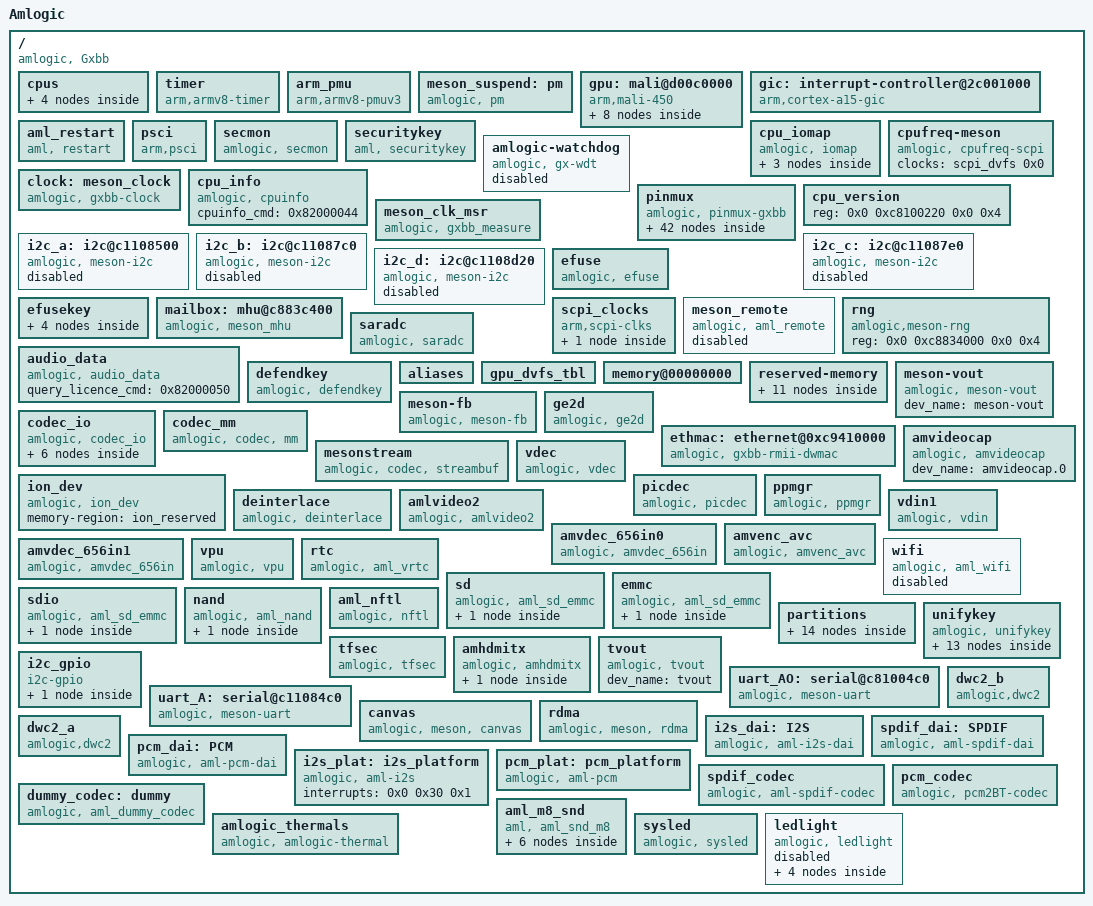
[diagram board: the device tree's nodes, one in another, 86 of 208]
/dts-v1/;

#include <dt-bindings/clock/gxbb.h>
#include <dt-bindings/gpio/gxbb.h>
#include <dt-bindings/gpio/gpio.h>
#include <dt-bindings/reset/aml_gxbb.h>
#include <dt-bindings/thermal/thermal.h>
#include <dt-bindings/interrupt-controller/arm-gic.h>
#include <dt-bindings/input/input.h>
#include <dt-bindings/input/meson_rc.h>

/ {
	model = "Amlogic";
	compatible = "amlogic, Gxbb";
	amlogic-dt-id = "gxbb_p201_q5";
	interrupt-parent = <&gic>;
	#address-cells = <0x2>;
	#size-cells = <0x2>;

	cpus: cpus {
		#address-cells = <0x2>;
		#size-cells = <0x0>;
		#cooling-cells = <2>;		/* min followed by max */

		cpu0: cpu@0 {
			device_type = "cpu";
			compatible = "arm,cortex-a53", "arm,armv8";
			reg = <0x0 0x0>;
			enable-method = "psci";
		};

		cpu1: cpu@1 {
			device_type = "cpu";
			compatible = "arm,cortex-a53", "arm,armv8";
			reg = <0x0 0x1>;
			enable-method = "psci";
		};

		cpu2: cpu@2 {
			device_type = "cpu";
			compatible = "arm,cortex-a53", "arm,armv8";
			reg = <0x0 0x2>;
			enable-method = "psci";
		};

		cpu3: cpu@3 {
			device_type = "cpu";
			compatible = "arm,cortex-a53", "arm,armv8";
			reg = <0x0 0x3>;
			enable-method = "psci";
		};
	};

	timer {
		compatible = "arm,armv8-timer";
		interrupts = <GIC_PPI 13 0xff01>,
				<GIC_PPI 14 0xff01>,
				<GIC_PPI 11 0xff01>,
				<GIC_PPI 10 0xff01>;
	};

	arm_pmu {
		compatible = "arm,armv8-pmuv3";
		interrupts = <0x0 0x89 0x4>,
					<0x0 0x8a 0x4>,
					<0x0 0x99 0x4>,
					<0x0 0x9a 0x4>;
	};

	meson_suspend: pm {
		compatible = "amlogic, pm";
		device_name = "aml_pm";
		gxbaby-suspend;
		reg = <0x0 0xc81000a8 0x0 0x4>,
			<0x0 0xc810023c 0x0 0x4>;
	};

	gpu: mali@d00c0000 {
		#cooling-cells = <2>;					/* min followed by max */
		compatible = "arm,mali-450";
		interrupt-parent = <&gic>;
		reg = <0x0 0xd00c0000 0x0 0x40000>,		/*mali APB bus base address*/
			<0x0 0xc883c000 0x0 0x4 >,			/*hiubus base address for gpu clk cntl*/
			<0x0 0xc8100000 0x0 0x4>;			/*aobus  base address for gpu pmu domain*/
												/*hiubus base address for gpu clk cntl*/
		interrupts = <0x0 0xa0 0x4 0x0 0xa1 0x4 0x0 0xa2 0x4 0x0 0xa3 0x4 0x0 0xa4 0x4 0x0 0xa5 0x4 0x0 0xa6 0x4 0x0 0xa7 0x4 0x0 0xa8 0x4 0x0 0xa9 0x4>;
		interrupt-names = "IRQGP", "IRQGPMMU", "IRQPP", "IRQPMU", "IRQPP0", "IRQPPMMU0", "IRQPP1", "IRQPPMMU1", "IRQPP2", "IRQPPMMU2";
		pmu_domain_config = <0x1 0x2 0x4 0x4 0x0 0x0 0x0 0x0 0x0 0x1 0x2 0x0>;
		pmu_switch_delay = <0xffff>;
		num_of_pp = <0x3>;
		def_clock = <0x3>;
		sc_mpp = <0x3>;							/* number of pp used most of time.*/
		tbl = <&clk125_cfg &clk285_cfg &clk400_cfg &clk500_cfg &clk666_cfg &clk800_cfg>;
		clocks = <&clock CLK_FPLL_DIV3>,
				<&clock CLK_FPLL_DIV4>,
				<&clock CLK_FPLL_DIV5>,
				<&clock CLK_FPLL_DIV7>,
				<&clock GP0_PLL>,
				<&clock CLK_MALI>,
				<&clock CLK_MALI_0>,
				<&clock CLK_MALI_1>;
		clock-names = "fclk_div3", "fclk_div4", "fclk_div5", "fclk_div7", "gp0_pll", "clk_mali", "clk_mali_0", "clk_mali_1";
		/*control_interval x keep_count == 900 - 1000ms */
		control_interval = <0xc8>;
		dvfs_tbl = <&gpu_dvfs_tbl>;

		clk125_cfg: clk125_cfg {
			clk_freq = <0x7735940>;
			clk_parent = "fclk_div4";
			clkp_freq = <0x1dcd6500>;
			voltage = <0x47e>;
			keep_count = <0x5>;
			threshold = <0x1e 0x78>;
		};

		clk250_cfg: clk250_cfg {
			clk_freq = <0xee6b280>;
			clk_parent = "fclk_div4";
			clkp_freq = <0x1dcd6500>;
			voltage = <0x47e>;
			keep_count = <0x5>;
			threshold = <0x50 0xaa>;
			/*125 = 250*(125/250), 50= 60-10*/
		};

		clk285_cfg: clk285_cfg {
			clk_freq = <0x10fcc140>;
			clk_parent = "fclk_div7";
			clkp_freq = <0x10fcc140>;
			voltage = <0x47e>;
			keep_count = <0x5>;
			threshold = <0x64 0xbe>;
			/*109 = 250*(125/285)*/
		};

		clk400_cfg: clk400_cfg {
			clk_freq = <0x17d78400>;
			clk_parent = "fclk_div5";
			clkp_freq = <0x17d78400>;
			voltage = <0x47e>;
			keep_count = <0x5>;
			threshold = <0x98 0xcf>;
			/*178 = 250*(285/400)*/
		};

		clk500_cfg: clk500_cfg {
			clk_freq = <0x1dcd6500>;
			clk_parent = "fclk_div4";
			clkp_freq = <0x1dcd6500>;
			voltage = <0x47e>;
			keep_count = <0x5>;
			threshold = <0xb4 0xdc>;
			/*200=250*(400/500)*/
		};

		clk666_cfg: clk666_cfg {
			clk_freq = <0x27b25a80>;
			clk_parent = "fclk_div3";
			clkp_freq = <0x27b25a80>;
			voltage = <0x47e>;
			keep_count = <0x5>;
			threshold = <0xd2 0xec>;
			/*187.5=250*(500/666.6)*/
		};

		clk750_cfg:clk750_cfg {
			clk_freq = <0x2c588a00>;
			clk_parent = "gp0_pll";
			clkp_freq = <0x2c588a00>;
			voltage = <0x47e>;
			keep_count = <0x1>;
			threshold = <0xd5 0xff>;
			/*223=250*(666.0/744.0), 223+7=230*/
		};

		clk800_cfg: clk800_cfg {
			clk_freq = <0x2f34f600>;
			clk_parent = "gp0_pll";
			clkp_freq = <0x2f34f600>;
			voltage = <0x47e>;
			keep_count = <0x5>;
			threshold = <0xe6 0xff>;
		};
	};

	gic: interrupt-controller@2c001000 {
		compatible = "arm,cortex-a15-gic", "arm,cortex-a9-gic";
		#interrupt-cells = <0x3>;
		#address-cells = <0x0>;
		interrupt-controller;
		reg = <0x0 0xc4301000 0x0 0x1000>,
			<0x0 0xc4302000 0x0 0x100>;
		interrupts = <GIC_PPI 0x9 0xf04>;
	};

	aml_restart {
		compatible = "aml, restart";
		sys_reset = <0x84000009>;
		sys_poweroff = <0x84000008>;
	};

	psci {
		compatible = "arm,psci";
		method = "smc";
		cpu_suspend = <0xc4000001>;
		cpu_off = <0x84000002>;
		cpu_on = <0xc4000003>;
		migrate = <0xc4000005>;
	};

	secmon {
		compatible = "amlogic, secmon";
		memory-region = <&secmon_reserved>;
		in_base_func = <0x82000020>;
		out_base_func = <0x82000021>;
	};
/*
	securitykey {
		compatible = "aml, securitykey";
		storage_query = <0x82000060>;
		storage_read = <0x82000061>;
		storage_write = <0x82000062>;
		storage_tell = <0x82000063>;
		storage_verify = <0x82000064>;
		storage_status = <0x82000065>;
		storage_list = <0x82000067>;
		storage_remove = <0x82000068>;
		storage_in_func = <0x82000023>;
		storage_out_func = <0x82000024>;
		storage_block_func = <0x82000025>;
		storage_size_func = <0x82000027>;
	};
*/
	securitykey {
		compatible = "aml, securitykey";
		storage_query = <0x82000060>;
		storage_read = <0x82000061>;
		storage_write = <0x82000062>;
		storage_tell = <0x82000063>;
		storage_verify = <0x82000064>;
		storage_status = <0x82000065>;
		storage_list = <0x82000067>;
		storage_remove = <0x82000068>;
		storage_in_func = <0x82000023>;
		storage_out_func = <0x82000024>;
		storage_block_func = <0x82000025>;
		storage_size_func = <0x82000027>;
		storage_set_enctype = <0x8200006A>;
		storage_get_enctype = <0x8200006B>;
		storage_version = <0x8200006C>;
	};

	cpu_iomap {
		compatible = "amlogic, iomap";
		#address-cells = <0x2>;
		#size-cells = <0x2>;
		ranges;

		io_cbus_base {
			reg = <0x0 0xc1100000 0x0 0x100000>;
		};

		io_apb_base {
			reg = <0x0 0xd0000000 0x0 0x200000>;
		};

		io_aobus_base {
			reg = <0x0 0xc8100000 0x0 0x100000>;
		};
	};

	cpufreq-meson {
		compatible = "amlogic, cpufreq-scpi";
		status = "okay";
		clocks = <&scpi_dvfs 0x0>;
		clock-names = "cpu_clk";
	};

	amlogic-watchdog {
		compatible = "amlogic, gx-wdt";
		status = "disable";
		default_timeout = <0xa>;
		reset_watchdog_method = <0x1>;		//0:sysfs, 1:kernel
		reset_watchdog_time = <0x2>;
		shutdown_timeout = <0xa>;
		firmware_timeout = <0x6>;
		suspend_timeout = <0x6>;
		reg = <0x0 0xc11098d0 0x0 0x10>;
		clocks = <&clock CLK_XTAL>;
	};

	clock: meson_clock {
		compatible = "amlogic, gxbb-clock";
		reg = <0x0 0xc883c000 0x0 0x1000>,		/* HIU BUS*/
			<0x0 0xc8100000 0x0 0x1000>;		//AOBUS
		#clock-cells = <0x1>;
		#reset-cells = <0x1>;
		sys_max = <0x5b8d8000>;
	};

	cpu_info {
		compatible = "amlogic, cpuinfo";
		cpuinfo_cmd = <0x82000044>;
	};

	pinmux: pinmux {
		compatible = "amlogic, pinmux-gxbb";
		dev_name = "pinmux";
		#pinmux-cells = <0x2>;
		#address-cells = <0x2>;
		#size-cells = <0x2>;
		reg = <0x0 0xc1109880 0x0 0x10>;
		ranges;

		gpio: banks@c11080b0 {
			reg = <0x0 0xc88344b0 0x0 0x28>,
				<0x0 0xc88344e8 0x0 0x14>,
				<0x0 0xc8834520 0x0 0x14>,
				<0x0 0xc8834430 0x0 0x40>;
			reg-names = "mux", "pull", "pull-enable", "gpio";
			gpio-controller;
			#gpio-cells = <0x2>;
		};

		gpio_ao: ao-bank@c1108030 {
			reg = <0x0 0xc8100014 0x0 0x8>,
				<0x0 0xc810002c 0x0 0x4>,
				<0x0 0xc8100024 0x0 0x8>;
			reg-names = "mux", "pull", "gpio";
			gpio-controller;
			#gpio-cells = <0x2>;
		};

		eth_pins: eth_pins {
			amlogic,setmask = <0x6 0x3fff>;
			amlogic,clrmask = <6 0xc000>,
							<5 0x3c0000f0>,
							<4  0x300>;
			amlogic,pins = "GPIOZ_0", "GPIOZ_1", "GPIOZ_2",
				"GPIOZ_3", "GPIOZ_4", "GPIOZ_5", "GPIOZ_6",
				"GPIOZ_7", "GPIOZ_8", "GPIOZ_9", "GPIOZ_10",
				"GPIOZ_11", "GPIOZ_12", "GPIOZ_13", "GPIOZ_15";
		};

		remote_pins: remote_pin {
			amlogic,setmask = <AO 0x1>;
			amlogic,pins = "GPIOAO_7";
		};

		ao_uart_pins: ao_uart {
			amlogic,setmask = <AO 0x1800>;
			amlogic,pins = "GPIOAO_0", "GPIOAO_1";
		};

		ao_b_uart_pins: ao_b_uart {
			amlogic,setmask = <AO 0x1800000>;
			amlogic,pins = "GPIOAO_4", "GPIOAO_5";
		};

		a_uart_pins: a_uart {
			amlogic,setmask = <0x4 0x3c00>;
			amlogic,pins = "GPIOX_12", "GPIOX_13", "GPIOX_14", "GPIOX_15";
		};

		b_uart_pins: b_uart {
			amlogic,setmask = <0x2 0x30000000>;
			amlogic,pins = "GPIODV_24", "GPIODV_25";
		};

		c_uart_pins: c_uart {
			amlogic,setmask = <0x1 0xc0000>;
			amlogic,pins = "GPIOY_13", "GPIOY_14";
		};

		wifi_32k_pins: wifi_32k_pins {
			amlogic,setmask = <0x2 0x40000000>;
			amlogic,clrmask = <0x2 0x400000 0x3 0x8000>;
			amlogic,pins = "GPIOX_19";
		};

		sd_clk_cmd_pins: sd_clk_cmd_pins {
			amlogic,setmask = <0x2 0xc00 AO 0x1800>;
			amlogic,pins = "CARD_2", "CARD_3";		/* CARD_2:CLK, CARD_3:CMD */
			amlogic,enable-output = <0x1>;			/* 0:output, 1:input */
			amlogic,pullup = <0x1>;
			amlogic,pullupen = <0x1>;
		};

		sd_all_pins: sd_all_pins {
			amlogic,setmask = <0x2 0xfc00 0x10 0x1800>;
			amlogic,pins = "CARD_0", "CARD_1", "CARD_2", "CARD_3", "CARD_4", "CARD_5";
			amlogic,enable-output = <0x1>;			/* 0:output, 1:input */
			amlogic,pullup = <0x1>;
			amlogic,pullupen = <0x1>;
		};

		sd_1bit_pins: sd_1bit_pins {
			amlogic,setmask = <0x2 0x8c00 AO 0x1800>;
			amlogic,pins = "CARD_1", "CARD_2", "CARD_3";
			amlogic,enable-output = <0x1>;			/* 0:output, 1:input */
			amlogic,pullup = <0x1>;
			amlogic,pullupen = <0x1>;
		};

		sd_clk_cmd_uart_pins: sd_clk_cmd_uart_pins {
			amlogic,setmask = <0x2 0xc00 0x8 0x600>;
			amlogic,pins = "CARD_2", "CARD_3";		/* CARD_2:CLK, CARD_3:CMD*/
			amlogic,enable-output = <0x1>;			/* 0:output, 1:input */
			amlogic,pullup = <0x1>;
			amlogic,pullupen = <0x1>;
		};

		sd_1bit_uart_pins: sd_1bit_uart_pins {
			amlogic,setmask = <0x2 0x8c00 0x8 0x600>;
			amlogic,pins = "CARD_1", "CARD_2", "CARD_3";
			amlogic,enable-output = <0x1>;			/* 0:output, 1:input */
			amlogic,pullup = <0x1>;
			amlogic,pullupen = <0x1>;
		};

		sd_to_ao_uart_pins: sd_to_ao_uart_pins {
			amlogic,setmask = <0x10 0x1800>;
			amlogic,clrmask = <0x8 0x600>;
			amlogic,pins = "GPIOAO_0", "GPIOAO_1";
			amlogic,enable-output = <0x1>;			/* 0:output, 1:input */
			amlogic,pullup = <0x1>;
			amlogic,pullupen = <0x1>;
		};

		ao_to_sd_uart_pins: ao_to_sd_uart_pins {
			amlogic,setmask = <0x8 0x600>;
			amlogic,clrmask = <0x10 0x1800 0x2 0x3000>;
			amlogic,pins = "CARD_4", "CARD_5";
			amlogic,enable-output = <0x1>;			/* 0:output, 1:input */
			amlogic,pullup = <0x1>;
			amlogic,pullupen = <0x1>;
		};

		ao_to_sd_jtag_pins: ao_to_sd_jtag_pins {
			amlogic,setmask = <0x8 0x600>;
			amlogic,clrmask = <0x2 0xcc00 AO 0x1800>;
			amlogic,pins = "CARD_4", "CARD_5";
			amlogic,enable-output = <0x1>;			/* 0:output, 1:input */
			amlogic,pullup = <0x1>;
			amlogic,pullupen = <0x1>;
		};

		sd_to_ao_jtag_pins: sd_to_ao_jtag_pins {
			amlogic,setmask = <0x10 0x1800>;
			amlogic,clrmask = <0x8 0x600 0x2 0xcc00>;
			amlogic,pins = "GPIOAO_0", "GPIOAO_1";
			amlogic,enable-output = <0x1>;			/* 0:output, 1:input */
			amlogic,pullup = <0x1>;
			amlogic,pullupen = <0x1>;
		};

		emmc_clk_cmd_pins: emmc_clk_cmd_pins {
			amlogic,setmask = <0x4 0xc00c0000>;
			amlogic,pins = "BOOT_8", "BOOT_10";		/** BOOT_10:CMD, BOOT_8:CLK */
			amlogic,enable-output = <0x1>;			/* 0:output, 1:input */
			amlogic,pullup = <0x1>;
			amlogic,pullupen = <0x1>;
		};

		emmc_all_pins: emmc_all_pins {
			amlogic,setmask = <0x4 0xc00c0000>;		/*sdhc c*/
			amlogic,pins = "BOOT_0", "BOOT_1", "BOOT_2", "BOOT_3", "BOOT_4", "BOOT_5", "BOOT_6", "BOOT_7", "BOOT_8", "BOOT_10";
			amlogic,enable-output = <0x1>;			/* 0:output, 1:input */
			amlogic,pullup = <0x1>;
			amlogic,pullupen = <0x1>;
		};

		sdio_clk_cmd_pins: sdio_clk_cmd_pins {
			amlogic,setmask = <0x8 0x3>;
			amlogic,pins = "GPIOX_4", "GPIOX_5";	/** GPIOX_5:CMD, GPIOX_4:CLK */
			amlogic,enable-output = <0x1>;			/* 0:output, 1:input */
			amlogic,pullup = <0x1>;
			amlogic,pullupen = <0x1>;
		};

		sdio_all_pins: sdio_all_pins {
			amlogic,setmask = <0x8 0x3f>;
			amlogic,pins = "GPIOX_0", "GPIOX_1", "GPIOX_2", "GPIOX_3", "GPIOX_4", "GPIOX_5";
			amlogic,enable-output = <0x1>;			/* 0:output, 1:input */
			amlogic,pullup = <0x1>;
			amlogic,pullupen = <0x1>;
		};

		/*cam_gpio_b: cam_gpio_b{
				amlogic,setmask=<5 0xf0>;
				amlogic,clrmask=<4 0x300
						5 0xc000000
						6 0x1ff3>;
				amlogic,pins = "GPIOZ_0","GPIOZ_1","GPIOZ_3","GPIOZ_4","GPIOZ_5","GPIOZ_6","GPIOZ_7","GPIOZ_8","GPIOZ_9","GPIOZ_10","GPIOZ_11";
		};
		cam_gpio_a: cam_gpio_a{
				amlogic,setmask=<2 0x3f0000>;
				amlogic,clrmask=<1 0x7030ff
						3 0x37>;
				amlogic,pins = "GPIOY_1","GPIOY_0","GPIOY_2","GPIOY_15","GPIOY_16",
					"GPIOY_3","GPIOY_4","GPIOY_5","GPIOY_6",
					"GPIOY_7","GPIOY_8","GPIOY_9","GPIOY_10";
		};*/

		conf_nand_pulldown: conf_nand_pulldown {
			amlogic,pins = "BOOT_0", "BOOT_1", "BOOT_2", "BOOT_3", "BOOT_4",
							"BOOT_5", "BOOT_6", "BOOT_7", "BOOT_15";
			amlogic,pullup = <0x0>;
			amlogic,pullupen = <0x1>;
		};

		conf_nand_pullup: conf_nand_pullup {
			amlogic,pins = "BOOT_8", "BOOT_10";
			amlogic,pullup = <0x1>;
			amlogic,pullupen = <0x1>;
		};

		all_nand_pins: all_nand_pins {
			amlogic,setmask = <0x4 0x7ff00000>;
			amlogic,clrmask = <0x0 0x80000>,
							<0x4 0x800c0000>,
							<0x5 0xf>;
			amlogic,pins = "BOOT_0", "BOOT_1", "BOOT_2", "BOOT_3", "BOOT_4",
							"BOOT_5", "BOOT_6", "BOOT_7", "BOOT_8", "BOOT_9",
							"BOOT_10", "BOOT_11", "BOOT_12", "BOOT_13", "BOOT_14",
							"BOOT_15", "BOOT_16", "BOOT_17";
			amlogic,enable-output = <0x1>;
		};

		nand_cs_pins: nand_cs {
			amlogic,setmask = <0x4 0xc000000>;
			amlogic,clrmask = <0x4 0x40000>;
			amlogic,pins = "BOOT_8", "BOOT_9";
		};

		hdmitx_hpd: hdmitx_hpd {
			amlogic,setmask = <0x1 0x4000000>;
			amlogic,pins = "GPIOH_0";
		};

		hdmitx_ddc: hdmitx_ddc {
			amlogic,setmask = <0x1 0x3000000>;
			amlogic,pins = "GPIOH_1", "GPIOH_2";
		};

		hdmitx_aocec: hdmitx_aocec {
			amlogic,setmask = <0x10 0x8000>;
			amlogic,clrmask = <0x10 0x24000 0x11 0x1>;
			amlogic,pins = "GPIOAO_12";
		};

		hdmitx_eecec: hdmitx_eecec {
			amlogic,setmask = <0x10 0x4000>;
			amlogic,clrmask = <0x10 0x28000 0x11 0x1>;
			amlogic,pins = "GPIOAO_12";
		};

		/*p200 i2c-A multiplex with usb PWR*/
		a_i2c_master: a_i2c {
			amlogic,setmask = <0x7 0xc000000>;
			amlogic,clrmask = <0x0 0x18c0 0x2 0x30000000 0x5 0x1800>;
			amlogic,pins = "GPIODV_24", "GPIODV_25";
		};

		b_i2c_master: b_i2c {
			amlogic,setmask = <0x7 0x3000000>;
			amlogic,clrmask = <0x0 0x600 0x2 0xc000000 0x5 0x700>;
			amlogic,pins = "GPIODV_26", "GPIODV_27";
		};

		c_i2c_master: c_i2c {
			amlogic,setmask = <0x7 0xc00000>;
			amlogic,clrmask = <0x3 0x700000>;
			amlogic,pins = "GPIODV_28", "GPIODV_29";
		};

		d_i2c_master: d_i2c {
			amlogic,setmask = <0x4 0xc>;
			amlogic,clrmask = <0x2 0x3000000 0x3 0x1000>;
			amlogic,pins = "GPIOX_16", "GPIOX_17";
		};

		dvb_p_ts0_pins: dvb_p_ts0_pins {
			amlogic,setmask = <0x3 0x37>;
			amlogic,clrmask = <0x2 0xf0000 0x1 0x30ff>;
			amlogic,pins = "GPIOY_0", "GPIOY_1", "GPIOY_2", "GPIOY_3", "GPIOY_4", "GPIOY_5", "GPIOY_6", "GPIOY_7", "GPIOY_8", "GPIOY_9", "GPIOY_10";
		};
		/*
		i2c_slave_pin:s_i2c{
			amlogic,setmask=<AO 0x6>;
			amlogic,clrmask=<AO 0x1800060>;
			amlogic,pins="GPIOAO_4","GPIOAO_5";
		};
		*/

		dvb_s_ts0_pins: dvb_s_ts0_pins {
			amlogic,setmask = <0x3 0x17>;
			amlogic,clrmask = <0x2 0xf0000 0x1 0x7>;
			amlogic,pins = "GPIOY_0", "GPIOY_1", "GPIOY_2", "GPIOY_3";
		};

		audio_pins: audio_pin {
			amlogic,setmask = <AO 0x78000000>;
			amlogic,clrmask = <AO 0x40000>;
			amlogic,pins = "GPIOAO_8", "GPIOAO_9", "GPIOAO_10", "GPIOAO_11";
		};

		audio_suspend_pins: audio_suspend_pin {
			amlogic,clrmask = <AO 0x78000000>;
			amlogic,pins = "GPIOAO_8", "GPIOAO_9", "GPIOAO_10", "GPIOAO_11";
			amlogic,pullupen = <0x1>;
			amlogic,pullup = <0x0>;
		};

		audio_spdif_pins: audio_pin1 {
			amlogic,setmask = <0x1 0x200>;		/*spdif_out*/
			amlogic,clrmask = <0x1 0x10000>;
			amlogic,pins = "GPIOY_12";
		};

		audio_spdif_sus_pin: audio_spdif_sus_pin {
			amlogic,clrmask = <0x1 0x10200>;
			amlogic,pins = "GPIOY_12";
			amlogic,pullupen = <0x1>;
			amlogic,pullup = <0x0>;
		};

		audio_btpcm_pins: audio_btpcm_pins {
			/* BT PCM PINMUX SETTING*/
			amlogic,setmask = <0x3 0x78000000>;
			amlogic,clrmask = <0x3 0x803280>,
							<0x4 0xc0>;
			amlogic,pins = "GPIOX_8", "GPIOX_9", "GPIOX_10", "GPIOX_11";
		};
	};

	cpu_version {
		reg = <0x0 0xc8100220 0x0 0x4>;
	};

	meson_clk_msr {
		compatible = "amlogic, gxbb_measure";
		reg = <0x0 0xc110875c 0x0 0x4>,
			<0x0 0xc1108764 0x0 0x4>;
	};

	i2c_a: i2c@c1108500 {
		compatible = "amlogic, meson-i2c";
		dev_name = "i2c-A";
		status = "disabled";
		reg = <0x0 0xc1108500 0x0 0x20>;
		device_id = <0x1>;
		pinctrl-names = "default";
		pinctrl-0 = <&a_i2c_master>;		/*p200 i2c-A multiplex with usb PWR*/
		#address-cells = <0x1>;
		#size-cells = <0x0>;
		use_pio = <0x0>;
		master_i2c_speed = <0x493e0>;
		clocks = <&clock CLK_81>;
		clock-names = "clk_i2c";
		resets = <&clock GCLK_IDX_I2C>;
	};

	i2c_b: i2c@c11087c0 {	/*I2C-B*/
		compatible = "amlogic, meson-i2c";
		dev_name = "i2c-B";
		status = "disabled";
		reg = <0x0 0xc11087c0 0x0 0x20>;
		device_id = <0x2>;
		pinctrl-names = "default";
		pinctrl-0 = <&b_i2c_master>;
		#address-cells = <0x1>;
		#size-cells = <0x0>;
		use_pio = <0x0>;
		master_i2c_speed = <0x493e0>;
		clocks = <&clock CLK_81>;
		clock-names = "clk_i2c";
		resets = <&clock GCLK_IDX_I2C>;
	};

	i2c_c: i2c@c11087e0 {	/*I2C-C*/
		compatible = "amlogic, meson-i2c";
		dev_name = "i2c-C";
		status = "disabled";
		reg = <0x0 0xc11087e0 0x0 0x20>;
		device_id = <0x3>;
		pinctrl-names = "default";
		pinctrl-0 = <&c_i2c_master>;
		#address-cells = <0x1>;
		#size-cells = <0x0>;
		use_pio = <0x0>;
		master_i2c_speed = <0x493e0>;
		clocks = <&clock CLK_81>;
		clock-names = "clk_i2c";
		resets = <&clock GCLK_IDX_I2C>;
	};

	i2c_d: i2c@c1108d20 {
		compatible = "amlogic, meson-i2c";
		dev_name = "i2c-D";
		status = "disabled";
		reg = <0x0 0xc1108d20 0x0 0x20>;
		device_id = <0x4>;
		pinctrl-names = "default";
		pinctrl-0 = <&d_i2c_master>;
		#address-cells = <0x1>;
		#size-cells = <0x0>;
		use_pio = <0x0>;
		master_i2c_speed = <0x493e0>;
		clocks = <&clock CLK_81>;
		clock-names = "clk_i2c";
		resets = <&clock GCLK_IDX_I2C>;
	};
	/*
	i2c_slave:i2c_slave@c8100540{
		compatible = "amlogic, meson-i2c-slave";
		status = "disabled";
		reg = <0x0 0xc8100540 0x0 0x20>;
		interrupts = <0 194 1>;
		pinctrl-names="default";
		pinctrl-0=<&i2c_slave_pin>;

	};
	*/
	efuse: efuse {
		compatible = "amlogic, efuse";
		read_cmd = <0x82000030>;
		write_cmd = <0x82000031>;
		get_max_cmd = <0x82000033>;
		key = <&efusekey>;
		resets = <&clock GCLK_IDX_EFUSE>;
		reset-names = "efuse_clk";
		status = "okay";
	};

	efusekey: efusekey {
		keynum = <0x4>;
		key0 = <&key0>;
		key1 = <&key1>;
		key2 = <&key2>;
		key3 = <&key3>;

		key0: key0 {
			keyname = "mac";
			offset = <0x0>;
			size = <0x6>;
		};

		key1: key1 {
			keyname = "mac_bt";
			offset = <0x6>;
			size = <0x6>;
		};

		key2: key2 {
			keyname = "mac_wifi";
			offset = <0xc>;
			size = <0x6>;
		};

		key3: key3 {
			keyname = "usid";
			offset = <0x12>;
			size = <0x14>;
		};
	};

	mailbox: mhu@c883c400 {
		compatible = "amlogic, meson_mhu";
		reg = <0x0 0xc883c400 0x0 0x4c>,		/* MHU registers */
				<0x0 0xc8013000 0x0 0x800>;		/* Payload area */
		interrupts = <0x0 0xd1 IRQ_TYPE_EDGE_RISING>,			/* low priority interrupt */
				<0x0 0xd2 IRQ_TYPE_EDGE_RISING>;					/* high priority interrupt */
		#mbox-cells = <0x1>;
		mbox-names = "cpu_to_scp_low", "cpu_to_scp_high";
		mboxes = <&mailbox 0x0 &mailbox 0x1>;
	};

	scpi_clocks {
		compatible = "arm,scpi-clks";

		scpi_dvfs: scpi_clocks@0 {
			compatible = "arm,scpi-clk-indexed";
			#clock-cells = <0x1>;
			clock-indices = <0x0>;
			clock-output-names = "vcpu";
		};
	};

	meson_remote {
		compatible = "amlogic, aml_remote";
		dev_name = "meson-remote";
		status = "disable";
		remote_ao_offset = <0x580>;
		interrupts = <0x0 0xc4 0x1>;
		pinctrl-names = "default";
		pinctrl-0 = <&remote_pins>;
		led_status_on = <0x0>;
		led_pin = <&gpio 0x58 0x0>;
	};

	/*
	remote:rc@c8100580 {
		compatible = "amlogic, aml_remote";
		dev_name = "meson-remote";
		reg = <0x0 0xc8100580 0x00 0x11>;
		status = "ok";
		protocol = <REMOTE_TYPE_NEC>;
		interrupts = <0 196 1>;
		pinctrl-names = "default";
		pinctrl-0 = <&remote_pins>;
		map = <&custom_maps>;
		release_delay = <80>;
		//set software decoder max frame time
		max_frame_time = <200>;
	};

	custom_maps:custom_maps {
		mapnum = <2>;
		map0 = <&map_0>;
		map1 = <&map_1>;
		map_0: map_0{
			mapname = "amlogic-remote-1";
			customcode = <0xfb04>;
			//keymap size
			size  = <44>;
			keymap = <REMOTE_KEY(0x47, KEY_0)
				REMOTE_KEY(0x13, KEY_1)
				REMOTE_KEY(0x10, KEY_2)
				REMOTE_KEY(0x11, KEY_3)
				REMOTE_KEY(0x0F, KEY_4)
				REMOTE_KEY(0x0C, KEY_5)
				REMOTE_KEY(0x0D, KEY_6)
				REMOTE_KEY(0x0B, KEY_7)
				REMOTE_KEY(0x08, KEY_8)
				REMOTE_KEY(0x09, KEY_9)
				REMOTE_KEY(0x5C, KEY_RIGHTCTRL)
				REMOTE_KEY(0x51, KEY_F7)
				REMOTE_KEY(0x49, KEY_BACKSPACE)
				REMOTE_KEY(0x06, KEY_PROPS)
				REMOTE_KEY(0x14, KEY_UNDO)
				REMOTE_KEY(0x44, KEY_UP)
				REMOTE_KEY(0x1D, KEY_DOWN)
				REMOTE_KEY(0x1C, KEY_LEFT)
				REMOTE_KEY(0x48, KEY_RIGHT)
				REMOTE_KEY(0x53, KEY_LEFTMETA)
				REMOTE_KEY(0x45, KEY_PAGEUP)
				REMOTE_KEY(0x19, KEY_PAGEDOWN)
				REMOTE_KEY(0x16, KEY_HOME)//
				REMOTE_KEY(0x52, KEY_PAUSE)
				REMOTE_KEY(0x05, KEY_HANGEUL)
				REMOTE_KEY(0x59, KEY_HANJA)
				REMOTE_KEY(0x1b, KEY_SCALE)
				REMOTE_KEY(0x04, KEY_KPCOMMA)
				REMOTE_KEY(0x1A, KEY_POWER)
				REMOTE_KEY(0x0A, KEY_TAB)
				REMOTE_KEY(0x0e, KEY_MUTE)
				REMOTE_KEY(0x15, KEY_F5)
				REMOTE_KEY(0x1F, KEY_HOME)
				REMOTE_KEY(0x1e, KEY_FRONT)
				REMOTE_KEY(0x07, KEY_COPY)
				REMOTE_KEY(0x12, KEY_OPEN)
				REMOTE_KEY(0x54, KEY_PASTE)
				REMOTE_KEY(0x02, KEY_FIND)
				REMOTE_KEY(0x4f, KEY_A)
				REMOTE_KEY(0x42, KEY_B)
				REMOTE_KEY(0x5d, KEY_C)
				REMOTE_KEY(0x4c, KEY_D)
				REMOTE_KEY(0x58, KEY_CUT)
				REMOTE_KEY(0x55, KEY_CALC)>;
		};
		map_1: map_1{
			mapname = "amlogic-remote-2";
			customcode = <0xfe01>;
			size  = <53>;
			keymap = <REMOTE_KEY(0x01, KEY_1)
				REMOTE_KEY(0x02, KEY_2)
				REMOTE_KEY(0x03, KEY_3)
				REMOTE_KEY(0x04, KEY_4)
				REMOTE_KEY(0x05, KEY_5)
				REMOTE_KEY(0x06, KEY_6)
				REMOTE_KEY(0x07, KEY_7)
				REMOTE_KEY(0x08, KEY_8)
				REMOTE_KEY(0x09, KEY_9)
				REMOTE_KEY(0x0a, KEY_0)
				REMOTE_KEY(0x1F, KEY_FN_F1)
				REMOTE_KEY(0x15, KEY_MENU)
				REMOTE_KEY(0x16, KEY_TAB)
				REMOTE_KEY(0x0c, KEY_CHANNELUP)
				REMOTE_KEY(0x0d, KEY_CHANNELDOWN)
				REMOTE_KEY(0x0e, KEY_VOLUMEUP)
				REMOTE_KEY(0x0f, KEY_VOLUMEDOWN)
				REMOTE_KEY(0x11, KEY_HOME)
				REMOTE_KEY(0x1c, KEY_RIGHT)
				REMOTE_KEY(0x1b, KEY_LEFT)
				REMOTE_KEY(0x19, KEY_UP)
				REMOTE_KEY(0x1a, KEY_DOWN)
				REMOTE_KEY(0x1d, KEY_ENTER)
				REMOTE_KEY(0x17, KEY_MUTE)
				REMOTE_KEY(0x49, KEY_FINANCE)
				REMOTE_KEY(0x43, KEY_BACK)
				REMOTE_KEY(0x12, KEY_FN_F4)
				REMOTE_KEY(0x14, KEY_FN_F5)
				REMOTE_KEY(0x18, KEY_FN_F6)
				REMOTE_KEY(0x59, KEY_INFO)
				REMOTE_KEY(0x5a, KEY_STOPCD)
				REMOTE_KEY(0x10, KEY_POWER)
				REMOTE_KEY(0x42, KEY_PREVIOUSSONG)
				REMOTE_KEY(0x44, KEY_NEXTSONG)
				REMOTE_KEY(0x1e, KEY_REWIND)
				REMOTE_KEY(0x4b, KEY_FASTFORWARD)
				REMOTE_KEY(0x58, KEY_PLAYPAUSE)
				REMOTE_KEY(0x46, KEY_PROPS)
				REMOTE_KEY(0x40, KEY_UNDO)
				REMOTE_KEY(0x38, KEY_SCROLLLOCK)
				REMOTE_KEY(0x57, KEY_FN)
				REMOTE_KEY(0x5b, KEY_FN_ESC)
				REMOTE_KEY(0x54, KEY_RED)
				REMOTE_KEY(0x4c, KEY_GREEN)
				REMOTE_KEY(0x4e, KEY_YELLOW)
				REMOTE_KEY(0x55, KEY_BLUE)
				REMOTE_KEY(0x53, KEY_BLUETOOTH)
				REMOTE_KEY(0x52, KEY_WLAN)
				REMOTE_KEY(0x39, KEY_CAMERA)
				REMOTE_KEY(0x41, KEY_SOUND)
				REMOTE_KEY(0x0b, KEY_QUESTION)
				REMOTE_KEY(0x00, KEY_CHAT)
				REMOTE_KEY(0x13, KEY_SEARCH)>;
		};
 	};
	*/

	rng {
		compatible = "amlogic,meson-rng";
		reg = <0x0 0xc8834000 0x0 0x4>;
	};

	audio_data: audio_data {
		compatible = "amlogic, audio_data";
		query_licence_cmd = <0x82000050>;
		status = "okay";
	};

	saradc: saradc {
		compatible = "amlogic, saradc";
		status = "okay";
		interrupts = <0x0 0x9 0x1>;
		interrupt-names = "saradc_int";
		clocks = <&clock CLK_XTAL>;
		clock-names = "saradc_clk";
		resets = <&clock GCLK_IDX_SARADC>;
		reg = <0x0 0xc1108680 0x0 0x30>,
			<0x0 0xc883c3d8 0x0 0x8>;
	};

	defendkey: defendkey {
		compatible = "amlogic, defendkey";
		reg = <0x0 0xc8834500 0x0 0x4>;		/*RAND64_ADDR0*/
		mem_size = <0x0 0x100000>;
		status = "okay";
	};

	aliases {
		serial0 = &uart_AO;
		serial1 = &uart_A;
	};

	gpu_dvfs_tbl: gpu_dvfs_tbl {
		sc_mpp = <0x3>;				/* number of pp used most of time.*/
		tbl = <&clk285_cfg &clk400_cfg &clk500_cfg &clk666_cfg &clk800_cfg>;
	};

	memory@00000000 {
		device_type = "memory";
		linux,usable-memory = <0x0 0x1000000 0x0 0x3f000000>;
	};

	reserved-memory {
		#address-cells = <0x2>;
		#size-cells = <0x2>;
		ranges;
		/* global autoconfigured region for contiguous allocations */
		secmon_reserved: linux,secmon {
			compatible = "amlogic, aml_secmon_memory";
			reg = <0x0 0x10000000 0x0 0x200000>;
			no-map;
		};

		secos_reserved:linux,secos {
			status = "disable";
			compatible = "amlogic, aml_secos_memory";
			reg = <0x0 0x05300000 0x0 0x2000000>;
			no-map;
		};

		pstore: aml_pstore {
			compatible = "amlogic, pstore";
			reg = <0x0 0x20000000 0x0 0x100000>;
			no-map;
		};

		fb_reserved: linux,meson-fb {
			compatible = "amlogic, fb-memory";
			size = <0x0 0x1900000>;
			no-map;
		};

		di_reserved:linux,di {
			compatible = "amlogic, di-mem";
			/** 10x3133440=30M(0x1e) support 8bit **/
			size = <0x0 0x1e00000>;
			//no-map;
			multi-use;
		};

		ion_reserved: linux,ion-dev {
			compatible = "amlogic, idev-mem";
			size = <0x0 0x2000000>;
			multi-use;
		};
		/*  vdin1 CMA pool */
		vdin1_cma_reserved:linux,vdin1_cma {
			compatible = "shared-dma-pool";
			reusable;
			/* 1920x1080x2x4  =16+4 M */
			size = <0x0 0x1400000>;
			alignment = <0x0 0x400000>;
		};

		/*  POST PROCESS MANAGER */

		//ppmgr_reserved: linux,ppmgr {
 		//compatible = "amlogic, ppmgr_memory";
		//size = <0x0 0x2000000>;
		//};
		amlvideo2_reserved: linux,amlvideo2 {
			compatible = "amlogic, amlvideo2_memory";
			size = <0x0 0x1800000>;
		};

		codec_mm_cma: linux,codec_mm_cma {
			compatible = "shared-dma-pool";
			reusable;
			size = <0x0 0xc000000>;
			alignment = <0x0 0x400000>;
			linux,contiguous-region;
		};

		picdec_cma_reserved:linux,picdec {
			compatible = "shared-dma-pool";
			reusable;
			size = <0x0 0x0>;
			alignment = <0x0 0x0>;
			linux,contiguous-region;
		};

		/* codec shared reserved */
		codec_mm_reserved:linux,codec_mm_reserved {
			compatible = "amlogic, codec-mm-reserved";
			size = <0x0 0x4100000>;
			alignment = <0x0 0x100000>;
		};
	};

	meson-vout {
		compatible = "amlogic, meson-vout";
		dev_name = "meson-vout";
		status = "okay";
	};

	meson-fb {
		compatible = "amlogic, meson-fb";
		memory-region = <&fb_reserved>;
		dev_name = "meson-fb";
		status = "okay";
		interrupts = <0x0 0x3 0x1>,
					<0x0 0x59 0x1>;
		interrupt-names = "viu-vsync", "rdma";
		mem_size = <0x1800000 0x100000>;		/* fb0/fb1 memory size */
		display_mode_default = "1080p60hz";
		scale_mode = <0x1>;				/** 0:VPU free scale 1:OSD free scale 2:OSD super scale */
		display_size_default = <0x780 0x438 0x780 0xca8 0x20>;	//1920*1080*4*3 = 0x17BB000
	};

	ge2d {
		compatible = "amlogic, ge2d";
		dev_name = "ge2d";
		status = "okay";
		interrupts = <0x0 0x96 0x1>;
		interrupt-names = "ge2d";
		clocks = <&clock CLK_VAPB_0 &clock CLK_GE2D>;
		clock-names = "clk_vapb_0", "clk_ge2d";
		resets = <&clock GCLK_IDX_GE2D>;
		reset-names = "ge2d";
	};

	codec_io {
		compatible = "amlogic, codec_io";
		#address-cells = <0x2>;
		#size-cells = <0x2>;
		ranges;

		io_cbus_base {
			reg = <0x0 0xc1100000 0x0 0x100000>;
		};

		io_dos_base {
			reg = <0x0 0xc8820000 0x0 0x10000>;
		};

		io_hiubus_base {
			reg = <0x0 0xc883c000 0x0 0x2000>;
		};

		io_aobus_base {
			reg = <0x0 0xc8100000 0x0 0x100000>;
		};

		io_vcbus_base {
			reg = <0x0 0xd0100000 0x0 0x40000>;
		};

		io_dmc_base {
			reg = <0x0 0xc8838000 0x0 0x400>;
		};
	};

	codec_mm {
		compatible = "amlogic, codec, mm";
		memory-region = <&codec_mm_cma &codec_mm_reserved>;
		dev_name = "codec_mm";
		status = "okay";
	};

	ethmac: ethernet@0xc9410000 {
		compatible = "amlogic, gxbb-rmii-dwmac";
		reg = <0x0 0xc9410000 0x0 0x10000 0x0 0xc8834540 0x0 0x8>;
		interrupts = <0x0 0x8 0x1>;
		phy-mode = "rmii";
		pinctrl-names = "eth_pins";
		pinctrl-0 = <&eth_pins>;
		rst_pin-gpios = <&gpio GPIOZ_14 0x0>;
		mc_val = <0x1800>;
		resets = <&clock GCLK_IDX_ETHERNET>;
		reset-names = "ethpower";
		interrupt-names = "macirq";
		clocks = <&clock CLK_81>;
		clock-names = "ethclk81";
	};

	mesonstream {
		compatible = "amlogic, codec, streambuf";
		dev_name = "mesonstream";
		status = "okay";
		resets = <&clock GCLK_IDX_HIU_PARSER_TOP>,
			<&clock GCLK_IDX_VPU_INTR>,
			<&clock GCLK_IDX_DEMUX>,
			<&clock GCLK_IDX_DOS>;
		reset-names = "parser_top", "vpu_intr", "demux", "vdec";
	};

	amvideocap {
		compatible = "amlogic, amvideocap";
		dev_name = "amvideocap.0";
		status = "okay";
	};

	ion_dev {
		compatible = "amlogic, ion_dev";
		memory-region = <&ion_reserved>;
	};

	vdec {
		compatible = "amlogic, vdec";
		dev_name = "vdec.0";
		status = "okay";
		interrupts = <0x0 0x3 0x1>,
			<0x0 0x17 0x1>,
			<0x0 0x20 0x1>,
			<0x0 0x2b 0x1>,
			<0x0 0x2c 0x1>,
			<0x0 0x2d 0x1>;
		interrupt-names = "vsync", "demux", "parser", "mailbox_0", "mailbox_1", "mailbox_2";
	};

	picdec {
		compatible = "amlogic, picdec";
		memory-region = <&picdec_cma_reserved>;
		dev_name = "picdec";
		status = "okay";
	};

	ppmgr {
		compatible = "amlogic, ppmgr";		//to match of_device_id's compatible member
		memory-region = <&ion_reserved>;
		dev_name = "ppmgr";
		status = "okay";
	};

	deinterlace {
		compatible = "amlogic, deinterlace";
		status = "okay";
		memory-region = <&di_reserved>;
		//post-wr-surpport = <1>;
		interrupts = <0x0 0x2e 0x1>,
					<0x0 0x6 0x1>;
		interrupt-names = "de_irq", "timerc";
		/* nr_size(byte) = 1920*544*2(yuv422 8bit) | 1920*544*2*12/8(yuv422 10bit) | 1920*544*2*10/8(yuv422 10bit full pack mode) */
		/* mtn_size(byte) = 1920*544/2 */
		/* count_size(byte) = 1920*544/2 */
		buffer-size = <0x2fd000>;
		hw-version = <0x2>;
	};

	amlvideo2 {
		compatible = "amlogic, amlvideo2";
		memory-region = <&amlvideo2_reserved>;
		dev_name = "amlvideo2";
		status = "okay";
	};
	/*
	vdin0 {
		compatible = "amlogic, vdin";
		memory-region = <&vdin0_cma_reserved>;
		dev_name = "vdin0";
		status = "ok";
		reserve-iomap = "true";
		interrupts = <0 83 1>;
		rdma-irq = <2>;
		clocks = <&clock CLK_XTAL>,
			<&clock CLK_VID_LOCK_CLK>;
		clock-names = "xtal", "cts_vid_lock_clk";
		vdin_id = <0>;
	};
	*/
	vdin1 {
		compatible = "amlogic, vdin";
		memory-region = <&vdin1_cma_reserved>;
		dev_name = "vdin1";
		status = "ok";
		reserve-iomap = "true";
		interrupts = <0x0 0x55 0x1>;
		rdma-irq = <0x4>;
		clocks = <&clock CLK_XTAL
				&clock CLK_VID_LOCK_CLK>;
		clock-names = "xtal", "cts_vid_lock_clk";
		vdin_id = <0x1>;
	};

	amvdec_656in0 {
		compatible = "amlogic, amvdec_656in";
		dev_name = "amvdec_656in0";
		status = "ok";
		reg = <0x0 0xd0048000 0x0 0x7c>;
		clocks = <&clock CLK_FPLL_DIV2
				&clock CLK_BT656_CLK0>;
		clock-names = "fclk_div2", "cts_bt656_clk0";
		bt656_id = <0x0>;
	};

	amvdec_656in1 {
		compatible = "amlogic, amvdec_656in";
		dev_name = "amvdec_656in1";
		status = "ok";
		reg = <0x0 0xd0050000 0x0 0x7c>;
		clocks = <&clock CLK_FPLL_DIV2
				&clock CLK_BT656_CLK1>;
		clock-names = "fclk_div2", "cts_bt656_clk1";
		bt656_id = <0x1>;
	};

	amvenc_avc {
		compatible = "amlogic, amvenc_avc";
		//memory-region = <&amvenc_avc_reserved>;
		//memory-region = <&avc_cma_reserved>;
		dev_name = "amvenc_avc";
		status = "okay";
		interrupts = <0x0 0x2d 0x1>;
		interrupt-names = "mailbox_2";
	};

	vpu {
		compatible = "amlogic, vpu";
		dev_name = "vpu";
		status = "ok";
		clk_level = <0x7>;
		/*	0: 100.0M	1: 166.7M	2: 200.0M
			3: 250.0M	4: 333.3M	5: 400.0M
			6: 500.0M	7: 666.7M
		*/
	};
	/*
	bt-dev{
		compatible = "amlogic, bt-dev";
		dev_name = "bt-dev";
		status = "ok";
		gpio_reset = <&gpio GPIOX_20 GPIO_ACTIVE_HIGH>;
	};
	*/
	rtc {
		compatible = "amlogic, aml_vrtc";
		alarm_reg_addr = <0xc81000a8>;
		timer_e_addr = <0xc1109988>;
		init_date = "2018/01/01";
		status = "okay";
	};

	wifi {
		compatible = "amlogic, aml_wifi";
		dev_name = "aml_wifi";
		status = "disable";
		interrupt_pin = <&gpio GPIOX_7 GPIO_ACTIVE_HIGH>;
		interrupts = <0x0 0x44 0x4>;
		irq_trigger_type = "GPIO_IRQ_HIGH";
		power_on_pin = <&gpio GPIOX_6 GPIO_ACTIVE_HIGH>;
		dhd_static_buf;
		pinctrl-names = "wifi_32k_pins";
		pinctrl-0 = <&wifi_32k_pins>;
	};
	/*
	wifi{
		compatible = "amlogic, aml_wifi";
		dev_name = "aml_wifi";
		status = "okay";
		interrupt_pin = <&gpio GPIOX_7 GPIO_ACTIVE_HIGH>;
		interrupts = < 0 68 4>;
		irq_trigger_type = "GPIO_IRQ_LOW";
		power_on_pin = <&gpio GPIOX_6 GPIO_ACTIVE_HIGH>;
		dhd_static_buf;
		pinctrl-names = "wifi_32k_pins";
		pinctrl-0 = <&wifi_32k_pins>;
		pwm_config = <&wifi_pwm_conf>;
	};
 	wifi_pwm_conf: wifi_pwm_conf{
		pwm_channel = <PWM_E>;
		pwm_channel_conf = <30519 15260>;
	};
	*/
	sd {
		compatible = "amlogic, aml_sd_emmc";
		dev_name = "aml_newsd.0";
		status = "okay";
		reg = <0x0 0xd0072000 0x0 0x2000>;
		interrupts = <0x0 0xd9 0x1>,
					<0x0 0x43 0x1>,
					<0x0 0x45 0x1>;
		pinctrl-names = "sd_clk_cmd_pins", "sd_all_pins", "sd_1bit_pins", "sd_clk_cmd_uart_pins",
					"sd_1bit_uart_pins", "sd_to_ao_uart_pins", "ao_to_sd_uart_pins",
					"ao_to_sd_jtag_pins", "sd_to_ao_jtag_pins";
		pinctrl-0 = <&sd_clk_cmd_pins>;
		pinctrl-1 = <&sd_all_pins>;
		pinctrl-2 = <&sd_1bit_pins>;
		pinctrl-3 = <&sd_clk_cmd_uart_pins>;
		pinctrl-4 = <&sd_1bit_uart_pins>;
		pinctrl-5 = <&sd_to_ao_uart_pins>;
		pinctrl-6 = <&ao_to_sd_uart_pins>;
		pinctrl-7 = <&ao_to_sd_jtag_pins>;
		pinctrl-8 = <&sd_to_ao_jtag_pins>;

		sd {
			status = "okay";
			port = <0x1>;					/**0:sdio_a, 1:sdio_b, 2:sdio_c, 3:sdhc_a, 4:sdhc_b, 5:sdhc_c */
			pinname = "sd";
			ocr_avail = <0x200080>;			// 3.3:0x200000, 1.8+3.3:0x00200080
			caps = "MMC_CAP_4_BIT_DATA", "MMC_CAP_MMC_HIGHSPEED", "MMC_CAP_SD_HIGHSPEED";
					//"MMC_CAP_UHS_SDR12", "MMC_CAP_UHS_SDR25",
					//"MMC_CAP_UHS_SDR50", "MMC_CAP_UHS_SDR104";
			f_min = <0x61a80>;
			f_max = <0x5f5e100>;
			tx_phase = <0x0>;
			max_req_size = <0x20000>;		/**128KB*/
			gpio_dat3 = <&gpio CARD_4 GPIO_ACTIVE_HIGH>;
			jtag_pin = <&gpio CARD_0 GPIO_ACTIVE_HIGH>;
			gpio_cd = <&gpio CARD_6 GPIO_ACTIVE_HIGH>;
			irq_in = <0x3>;
			irq_out = <0x5>;
			card_type = <0x5>;
			/*	0:unknown, 1:mmc card(include eMMC), 2:sd card(include tSD),
				3:sdio device(ie:sdio-wifi), 4:SD combo (IO+mem) card,
				5:NON sdio device(means sd/mmc card), other:reserved
			*/
		};
	};

	emmc {
		compatible = "amlogic, aml_sd_emmc";
		dev_name = "aml_newsd.0";
		status = "okay";
		reg = <0x0 0xd0074000 0x0 0x2000>;
		interrupts = <0x0 0xda 0x1>;
		pinctrl-names = "emmc_clk_cmd_pins", "emmc_all_pins";
		pinctrl-0 = <&emmc_clk_cmd_pins>;
		pinctrl-1 = <&emmc_all_pins>;

		emmc {
			status = "okay";
			pinname = "emmc";
			ocr_avail = <0x200080>;			/**VDD voltage 3.3 ~ 3.4 */
			caps = "MMC_CAP_8_BIT_DATA", "MMC_CAP_MMC_HIGHSPEED", "MMC_CAP_SD_HIGHSPEED",
				"MMC_CAP_NONREMOVABLE", "MMC_CAP_1_8V_DDR", "MMC_CAP_HW_RESET",
				"MMC_CAP_ERASE", "MMC_CAP_CMD23";
			caps2 = "MMC_CAP2_HS200";
			f_min = <0x493e0>;
			f_max = <0xbebc200>;
			max_req_size = <0x20000>;		/**256KB*/
			gpio_dat3 = <&gpio BOOT_3 0x0>;
			hw_reset = <&gpio BOOT_9 0x0>;
			card_type = <0x1>;				/* 1:mmc card(include eMMC), 2:sd card(include tSD), */
		};
	};

	sdio {
		compatible = "amlogic, aml_sd_emmc";
		dev_name = "aml_newsd.0";
		status = "okay";
		reg = <0x0 0xd0070000 0x0 0x2000>;
		interrupts = <0x0 0xd8 0x4>;
		pinctrl-names = "sdio_clk_cmd_pins", "sdio_all_pins";
		pinctrl-0 = <&sdio_clk_cmd_pins>;
		pinctrl-1 = <&sdio_all_pins>;

		sdio {
			status = "okay";
			pinname = "sdio";
			ocr_avail = <0x200080>;		/*3.3:0x200000, 1.8+3.3:0x00200080 */
			caps = "MMC_CAP_4_BIT_DATA", "MMC_CAP_MMC_HIGHSPEED", "MMC_CAP_SD_HIGHSPEED", "MMC_CAP_NONREMOVABLE", "MMC_CAP_UHS_SDR12", "MMC_CAP_UHS_SDR25", "MMC_CAP_UHS_SDR50", "MMC_CAP_UHS_SDR104", "MMC_PM_KEEP_POWER", "MMC_CAP_SDIO_IRQ";
			f_min = <0x61a80>;
			f_max = <0xbebc200>;
			max_req_size = <0x20000>;	/**128KB*/
			card_type = <0x3>;			/*3:sdio device(ie:sdio-wifi), 4:SD combo (IO+mem) card, */
		};
	};

	nand {
		compatible = "amlogic, aml_nand";
		dev_name = "nand";
		status = "ok";
		reg = <0x0 0xd0074800 0x0 0x200>;
		interrupts = <0x0 0x22 0x1>;
		pinctrl-names = "nand_rb_mod", "nand_norb_mod", "nand_cs_pins_only";
		pinctrl-0 = <&conf_nand_pulldown &conf_nand_pullup &all_nand_pins>;
		pinctrl-1 = <&conf_nand_pulldown &conf_nand_pullup &all_nand_pins>;
		pinctrl-2 = <&nand_cs_pins>;
		device_id = <0x0>;
		plat-names = "nandnormal";
		plat-num = <0x1>;
		plat-part-0 = <&normal>;

		normal: normal {
			enable_pad = "ce0", "ce1", "ce2", "ce3";
			busy_pad = "rb0";
		};
	};

	aml_nftl {
		compatible = "amlogic, nftl";
		/* config nftl here */
	};

	partitions {
		parts = <0xe>;
		part-0 = <&logo>;
		part-1 = <&recovery>;
		part-2 = <&rsv>;
		part-3 = <&tee>;
		part-4 = <&crypt>;
		part-5 = <&misc>;
		part-6 = <&instaboot>;
		part-7 = <&boot>;
		part-8 = <&system>;
		part-9 = <&cache>;
		part-10 = <&ghost>;
		part-11 = <&info>;
		part-12 = <&params>;
		part-13 = <&data>;

		logo: logo {
			pname = "logo";
			size = <0x0 0x2000000>;
			mask = <0x1>;
		};

		recovery: recovery {
			pname = "recovery";
			size = <0x0 0x2000000>;
			mask = <0x1>;
		};

		rsv: rsv {
			pname = "rsv";
			size = <0x0 0x800000>;
			mask = <0x1>;
		};

		tee: tee {
			pname = "tee";
			size = <0x0 0x800000>;
			mask = <0x1>;
		};

		crypt: crypt {
			pname = "crypt";
			size = <0x0 0x2000000>;
			mask = <0x1>;
		};

		misc: misc {
			pname = "misc";
			size = <0x0 0x2000000>;
			mask = <0x1>;
		};

		instaboot: instaboot {
			pname = "instaboot";
			size = <0x0 0x20000000>;
			mask = <0x1>;
		};

		boot: boot {
			pname = "boot";
			size = <0x0 0x2000000>;
			mask = <0x1>;
		};

		system: system {
			pname = "system";
			size = <0x0 0x28000000>;
			mask = <0x1>;
		};

		cache: cache {
			pname = "cache";
			size = <0x0 0x20000000>;
			mask = <0x2>;
		};

		ghost: ghost {
			pname = "ghost";
			size = <0x0 0x20000000>;
			mask = <0x4>;
		};

		info: info {
			pname = "info";
			size = <0x0 0x4000000>;
			mask = <0x4>;
		};

		params: params {
			pname = "params";
			size = <0x0 0x4000000>;
			mask = <0x2>;
		};

		data: data {
			pname = "data";
			size = <0xffffffff 0xffffffff>;
			mask = <0x4>;
		};
	};

	unifykey {
		compatible = "amlogic, unifykey";
		status = "ok";
		unifykey-num = <0xd>;
		unifykey-index-0 = <&keysn_0>;
		unifykey-index-1 = <&keysn_1>;
		unifykey-index-2 = <&keysn_2>;
		unifykey-index-3 = <&keysn_3>;
		unifykey-index-4 = <&keysn_4>;
		unifykey-index-5 = <&keysn_5>;
		unifykey-index-6 = <&keysn_6>;
		unifykey-index-7 = <&keysn_7>;
		unifykey-index-8 = <&keysn_8>;
		unifykey-index-9 = <&keysn_9>;
		unifykey-index-10 = <&keysn_10>;
		unifykey-index-11 = <&keysn_11>;
		unifykey-index-12 = <&keysn_12>;

		keysn_0: key_0 {
			key-name = "usid";
			key-device = "normal";
			key-permit = "read", "write", "del";
		};

		keysn_1: key_1 {
			key-name = "mac";
			key-device = "normal";
			key-permit = "read", "write", "del";
		};

		keysn_2: key_2 {
			key-name = "hdcp";
			key-device = "secure";
			key-type = "sha1";
			key-permit = "read", "write", "del";
		};

		keysn_3: key_3 {
			key-name = "secure_boot_set";
			key-device = "efuse";
			key-permit = "write";
		};

		keysn_4: key_4 {
			key-name = "mac_bt";
			key-device = "normal";
			key-permit = "read", "write", "del";
			key-type = "mac";
		};

		keysn_5: key_5 {
			key-name = "mac_wifi";
			key-device = "normal";
			key-permit = "read", "write", "del";
			key-type = "mac";
		};

		keysn_6: key_6 {
			key-name = "hdcp2_tx";
			key-device = "normal";
			key-permit = "read", "write", "del";
		};

		keysn_7: key_7 {
			key-name = "hdcp2_rx";
			key-device = "normal";
			key-permit = "read", "write", "del";
		};

		keysn_8: key_8 {
			key-name = "widevinekeybox";
			key-device = "secure";
			key-permit = "read", "write", "del";
		};

		keysn_9: key_9 {
			key-name = "deviceid";
			key-device = "normal";
			key-permit = "read", "write", "del";
		};

		keysn_10: key_10 {
			key-name = "hdcp22_fw_private";
			key-device = "secure";
			key-permit = "read", "write", "del";
		};

		keysn_11: key_11 {
			key-name = "telecomkeybox";
			key-device = "secure";
			key-type = "raw";
			key-permit = "read", "write", "del";
		};

		keysn_12: key_12 {
			key-name = "stbid";
			key-device = "normal";
			key-permit = "read", "write", "del";
		};
	};
	//End unifykey

	//Unknow
	tfsec {
		compatible = "amlogic, tfsec";
		tap_get_sn = <0xb000ff01>;
		tap_decrypt_cloud_challenge = <0xb000ff02>;
		tap_decrypt_terminal_challenge = <0xb000ff03>;
		tap_burn_in = <0xb000ff04>;
		tap_burn_sn = <0xb000ff05>;
		tap_burn_ci = <0xb000ff06>;
		tap_burn_mac = <0xb000ff07>;
		tap_get_mac = <0xb000ff08>;
		tap_get_ci = <0xb000ff09>;
		tap_query_in = <0xb000ff0a>;
	};

	amhdmitx: amhdmitx {
		compatible = "amlogic, amhdmitx";
		dev_name = "amhdmitx";
		status = "okay";
		pinctrl-names = "hdmitx_hpd", "hdmitx_ddc";
		pinctrl-0=<&hdmitx_hpd>;
		pinctrl-1=<&hdmitx_ddc>;
		vend-data = <&vend_data>;
		/* HPD, 57 + 32 = 89;	CEC, 151 + 32 = 183*/
		interrupts = <0x0 0x39 0x1>;
		interrupt-names = "hdmitx_hpd";
		clocks = <&clock CLK_HDMITX_SYS &clock CLK_HDMITX_ENCP
			&clock CLK_HDMITX_ENCI &clock CLK_HDMITX_PIXEL
			&clock CLK_HDMITX_PHY &clock CLK_VID>;
		clock-names = "hdmitx_clk_sys", "hdmitx_clk_encp", "hdmitx_clk_enci", "hdmitx_clk_pixel", "hdmitx_clk_phy", "hdmitx_clk_vid";
		gpio_i2c_en = <0x1>;
		#address-cells = <0x2>;
		#size-cells = <0x2>;
		ranges;

		vend_data: vend_data {
			compatible = "amlogic, amlogic-cec";
			status = "okay";
			vendor_name = "Amlogic";		/* Max Chars: 8 */
			vendor_id = <0x0>;				/* Refer to http://standards.ieee.org/develop/regauth/oui/oui.txt   */
			product_desc = "GXBB Mbox";		/* Max Chars: 16 */
			cec_osd_string = "MBox";		/* Max Chars: 14 */
			interrupts = <0x0 0xc7 0x1>;
			interrupt-names = "hdmitx_cec";
			pinctrl-names = "hdmitx_aocec";
			pinctrl-0 = <&hdmitx_aocec>;
			reg = <0x0 0xc810023c 0x0 0x4>,
				<0x0 0xc8100000 0x0 0x200>;
		};
	};

	tvout {
		compatible = "amlogic, tvout";
		dev_name = "tvout";
		status = "okay";
	};

	i2c_gpio: i2c_gpio {
		compatible = "i2c-gpio";
		dev_name = "i2c-gpio";
		i2c-gpio,delay-us = <0xa>;		/* 50 kHz */
		gpios = <&gpio GPIOH_1 0x0
			&gpio GPIOH_2 0x0>;
		#address-cells = <0x2>;
		#size-cells = <0x2>;
		i2c-gpio,timeout-ms = <0xa>;

		i2c_gpio_edid: i2c_gpio_edid {
			compatible = "i2c-gpio-edid";
			reg = <0x50 0x0 0x0 0x0>;
		};
	};

	uart_AO: serial@c81004c0 {
		compatible = "amlogic, meson-uart";
		reg = <0x0 0xc81004c0 0x0 0x14>;
		interrupts = <0x0 0xc1 0x1>;
		status = "okay";
		clocks = <&clock 0x2>;
		clock-names = "clk_uart";
		fifosize = <0x40>;
		pinctrl-names = "default";
		//pinctrl-0 = <&ao_uart_pins>;
		support-sysrq = <0>;	/* 0 not support , 1 support */
	};

	uart_A: serial@c11084c0 {
		compatible = "amlogic, meson-uart";
		reg = <0x0 0xc11084c0 0x0 0x14>;
		interrupts = <0x0 0x1a 0x1>;
		status = "okay";
		clocks = <&clock CLK_XTAL>;
		clock-names = "clk_uart";
		fifosize = <0x80>;
		pinctrl-names = "default";
		pinctrl-0 = <&a_uart_pins>;
		resets = <&clock GCLK_IDX_UART0>;
	};

	canvas {
		compatible = "amlogic, meson, canvas";
		dev_name = "amlogic-canvas";
		status = "ok";
		reg = <0x0 0xc8838000 0x0 0x400>;
	};

	rdma {
		compatible = "amlogic, meson, rdma";
		dev_name = "amlogic-rdma";
		status = "ok";
		interrupts = <0x0 0x59 0x1>;
		interrupt-names = "rdma";
	};

	dwc2_b {
		compatible = "amlogic,dwc2";
		device_name = "dwc2_b";
		reg = <0x0 0xc9100000 0x0 0x40000>;
		interrupts = <0x0 0x1f 0x4>;
		status = "okay";
		pl-periph-id = <0x1>;	/** lm name */
		clock-src = "usb1";		/** clock src */
		port-id = <0x1>;		/** ref to mach/usb.h */
		port-type = <0x1>;		/** 0: otg, 1: host, 2: slave */
		port-speed = <0x0>;		/** 0: default, 1: high, 2: full */
		port-config = <0x0>;	/** 0: default */
		port-dma = <0x0>;		/** 0: default, 1: single, 2: incr, 3: incr4, 4: incr8, 5: incr16, 6: disable*/
		port-id-mode = <0x1>;	/** 0: hardware, 1: sw_host, 2: sw_slave*/
		phy-reg = <0xc0000020>;
		phy-reg-size = <0x20>;
		usb-fifo = <0x400>;
		host-only-core = <0x1>;
		pmu-apply-power = <0x1>;
		cpu-type = "gxbaby";
		resets = <&clock GCLK_IDX_USB_GENERAL>,
			<&clock GCLK_IDX_MISC_USB1_TO_DDR>,
			<&clock GCLK_IDX_USB1>;
		reset-names = "usb_general", "usb1", "usb1_to_ddr";
	};

	dwc2_a {
		compatible = "amlogic,dwc2";
		device_name = "dwc2_a";
		reg = <0x0 0xc9000000 0x0 0x40000>;
		interrupts = <0x0 0x1e 0x4>;
		status = "okay";
		pl-periph-id = <0x0>;	/** lm name */
		clock-src = "usb0";		/** clock src */
		port-id = <0x0>;		/** ref to mach/usb.h */
		port-type = <0x1>;		/** 0: otg, 1: host, 2: slave */
		port-speed = <0x0>;		/** 0: default, high, 1: full */
		port-config = <0x0>;	/** 0: default */
		port-dma = <0x0>;		/** 0: default, 1: single, 2: incr, 3: incr4, 4: incr8, 5: incr16, 6: disable*/
		port-id-mode = <0x1>;	/** 0: hardware, 1: sw_host, 2: sw_slave*/
		gpio-vbus-power = "GPIODV_24";
		gpios = <&gpio GPIODV_24 0x0>;
		gpio-work-mask = <0x1>;		/**0: work on pulldown,1:work on pullup*/
		phy-reg = <0xc0000000>;
		phy-reg-size = <0x20>;
		usb-fifo = <0x400>;
		cpu-type = "gxbaby";
		resets = <&clock GCLK_IDX_USB_GENERAL>,
			<&clock GCLK_IDX_MISC_USB0_TO_DDR>,
			<&clock GCLK_IDX_USB0>;
		reset-names = "usb_general", "usb0", "usb0_to_ddr";
	};
	/* AUDIO MESON8 DEVICES */
	i2s_dai: I2S {
		#sound-dai-cells = <0x0>;
		resets = <
			&clock GCLK_IDX_AIU_AI_TOP_GLUE
			&clock GCLK_IDX_AUD_BUF_ABD
			&clock GCLK_IDX_AIU_I2S_OUT
			&clock GCLK_IDX_AIU_AMCLK_MEASURE
			&clock GCLK_IDX_AIU_AIFIFO2
			&clock GCLK_IDX_AIU_AUD_MIXER
			&clock GCLK_IDX_AIU_MIXER_REG
			&clock GCLK_IDX_AIU_ADC
			&clock GCLK_IDX_AIU_TOP_LEVEL
			&clock GCLK_IDX_AIU_AOCLK
			&clock GCLK_IDX_AUD_IN>;
		reset-names = "top_glue", "aud_buf", "i2s_out", "amclk_measure", "aififo2", "aud_mixer", "mixer_reg", "adc", "top_level", "aoclk", "aud_in";
		clocks = <&clock CLK_MPLL2>,
			<&clock CLK_AMCLK>;
		clock-names = "mpll2", "mclk";
		compatible = "amlogic, aml-i2s-dai";
	};

	spdif_dai: SPDIF {
		#sound-dai-cells = <0x0>;
		compatible = "amlogic, aml-spdif-dai";
		resets = <&clock GCLK_IDX_AIU_IEC958
			&clock GCLK_IDX_AIU_ICE958_AMCLK>;
		reset-names = "iec958", "iec958_amclk";
		clocks = <&clock CLK_MPLL1>,
			<&clock CLK_I958>,
			<&clock CLK_AMCLK>,
			<&clock CLK_SPDIF>,
			<&clock CLK_81>;
		clock-names = "mpll1", "i958", "mclk", "spdif", "clk_81";
	};

	pcm_dai: PCM {
		#sound-dai-cells = <0x0>;
		compatible = "amlogic, aml-pcm-dai";
		pinctrl-names = "aml_audio_btpcm";
		pinctrl-0 = <&audio_btpcm_pins>;
		clocks = <&clock CLK_MPLL0>,
			<&clock CLK_PCM_MCLK>,
			<&clock CLK_PCM_SCLK>;
		clock-names = "mpll0", "pcm_mclk", "pcm_sclk";
		pcm_mode = <1>;		/* 0=slave mode, 1=master mode */
	};

	i2s_plat: i2s_platform {
		compatible = "amlogic, aml-i2s";
		interrupts = <0x0 0x30 0x1>;
	};

	pcm_plat: pcm_platform {
		compatible = "amlogic, aml-pcm";
	};

	spdif_codec: spdif_codec {
		#sound-dai-cells = <0x0>;
		compatible = "amlogic, aml-spdif-codec";
		pinctrl-names = "aml_audio_spdif", "aml_audio_spdif_suspend";
		pinctrl-0 = <&audio_spdif_pins>;
		pinctrl-1 = <&audio_spdif_sus_pin>;
	};

	pcm_codec: pcm_codec {
		#sound-dai-cells = <0x0>;
		compatible = "amlogic, pcm2BT-codec";
	};
	/* endof AUDIO MESON8 DEVICES */


	/* AUDIO board specific */
	dummy_codec: dummy {
		#sound-dai-cells = <0x0>;
		compatible = "amlogic, aml_dummy_codec";
		status = "okay";
	};

	aml_m8_snd {
		compatible = "aml, aml_snd_m8";
		status = "okay";
		aml-sound-card,format = "i2s";
		aml_sound_card,name = "AML-M8AUDIO";
		aml,audio-routing = "Ext Spk", "LOUTL", "Ext Spk", "LOUTR";
		mute_gpio-gpios = <&gpio GPIOH_3 0x0>;
		hp_disable;
		hp_paraments = <0x320 0x12c 0x0 0x5 0x1>;
		pinctrl-names = "aml_snd_m8", "aml_snd_suspend";
		pinctrl-0 = <&audio_pins>;
		pinctrl-1 = <&audio_suspend_pins>;
		cpu_list = <&cpudai0 &cpudai1 &cpudai2>;
		codec_list = <&codec0 &codec1 &codec2>;
		plat_list = <&i2s_plat &i2s_plat &pcm_plat>;

		cpudai0: cpudai0 {
			sound-dai = <&i2s_dai>;
		};
		cpudai1: cpudai1 {
			sound-dai = <&spdif_dai>;
		};
		cpudai2: cpudai2 {
			sound-dai = <&pcm_dai>;
		};
		codec0: codec0 {
			sound-dai = <&dummy_codec>;
		};
		codec1: codec1 {
			sound-dai = <&spdif_codec>;
		};
		codec2: codec2 {
			sound-dai = <&pcm_codec>;
		};
	};
	/* END OF AUDIO board specific */

	amlogic_thermals {
		compatible = "amlogic, amlogic-thermal";
		#thermal-cells = <0x7>;
		dev_name = "aml_thermal";
		trip_point = <0x46 0x177001 0x177001 0x1ff 0x1ff 0x3 0x2 0x50 0x13c681 0x13c681 0x1b3 0x1b3 0x2 0x1 0x5a 0xfbf41 0xfbf41 0x148 0x148 0x2 0x1 0x104 0xffffffff 0xffffffff 0xffffffff 0xffffffff 0xffffffff 0xffffffff>;
		cpu_cali_a = <0x0>;
		idle_interval = <0x3e8>;
		keep_mode;
		keep_mode_threshold = <0x55>;
		keep_mode_max_range = <0x1ec300 0x29a 0x4 0x3>;
		keep_mode_min_range = <0x1f4 0x190 0x1 0x2>;
	};

	/*
	aml_sensor0: aml-sensor@0 {
		compatible = "amlogic, aml-thermal";
		device_name = "thermal";
		#thermal-sensor-cells = <1>;
		cooling_devices {
			cpufreq_cool_cluster0 {
				min_state = <1000000>;
				dyn_coeff = <140>;
				cluster_id = <0>;
				node_name = "cpus";
				device_type = "cpufreq";
			};
			cpucore_cool_cluster0 {
				min_state = <1>;
				dyn_coeff = <0>;
				cluster_id = <0>;
				node_name = "cpu_core_cluster0";
				device_type = "cpucore";
			};
			gpufreq_cool {
				min_state = <400>;
				dyn_coeff = <437>;
				cluster_id = <0>;
				node_name = "mali";
				device_type = "gpufreq";
			};
			gpucore_cool {
				min_state = <1>;
				dyn_coeff = <0>;
				cluster_id = <0>;
				node_name = "thermal_gpu_cores";
				device_type = "gpucore";
			};
		};
		cpu_cluster0:cpu_core_cluster0 {
			#cooling-cells = <2>; // min followed by max
		};
		gpucore:thermal_gpu_cores {
			#cooling-cells = <2>; // min followed by max
		};
	};
	thermal-zones {
		soc_thermal {
			polling-delay = <1000>;
			polling-delay-passive = <100>;
			sustainable-power = <2150>;

			thermal-sensors = <&aml_sensor0 3>;

			trips {
				switch_on: trip-point@0 {
					temperature = <70000>;
					hysteresis = <1000>;
					type = "passive";
				};
				control: trip-point@1 {
					temperature = <80000>;
					hysteresis = <1000>;
					type = "passive";
				};
				hot: trip-point@2 {
					temperature = <85000>;
					hysteresis = <5000>;
					type = "hot";
				};
				critical: trip-point@3 {
					temperature = <260000>;
					hysteresis = <1000>;
					type = "critical";
				};
			};

			cooling-maps {
				cpufreq_cooling_map {
					trip = <&control>;
					cooling-device = <&cpus 0 4>;
					contribution = <1024>;
				};
				cpucore_cooling_map {
					trip = <&control>;
					cooling-device = <&cpu_cluster0 0 3>;
					contribution = <1024>;
				};
				gpufreq_cooling_map {
					trip = <&control>;
					cooling-device = <&gpu 0 4>;
					contribution = <1024>;
				};
				gpucore_cooling_map {
					trip = <&control>;
					cooling-device = <&gpucore 0 2>;
					contribution = <1024>;
				};
			};
		};
	};
	*/

	sysled {
		compatible = "amlogic, sysled";
		dev_name = "sysled";
		status = "okay";
		led_gpio = <&gpio_ao  GPIOZ_13  GPIO_ACTIVE_HIGH>;
		led_active_low = <GPIO_ACTIVE_LOW>;
	};

	ledlight {
		compatible = "amlogic, ledlight";
		dev_name = "ledlight";
		status = "disable";
		power_gpio_0 = <&gpio_rg>;
		net_gpio_0 = <&gpio_r>;
		net_gpio_1 = <&gpio_g>;
		ir_gpio_0 = <&gpio_b>;

		gpio_rg: gpio_rg {
			led_name = "power_led";
			led_gpio = <&gpio_ao GPIOZ_13 GPIO_ACTIVE_HIGH>;
			led_active = <GPIO_ACTIVE_LOW>;
			led_type = "R&G";
		};

		gpio_r: gpio_r {
			led_name = "net_led";
			led_gpio = <&gpio GPIOY_10 GPIO_ACTIVE_HIGH>;
			led_active = <GPIO_ACTIVE_HIGH>;
			led_type = [52 00];
		};

		gpio_g: gpio_g {
			led_name = "net_led";
			led_gpio = <&gpio GPIOY_7 GPIO_ACTIVE_HIGH>;
			led_active = <GPIO_ACTIVE_HIGH>;
			led_type = [47 00];
		};

		gpio_b: gpio_b {
			led_name = "ir_led";
			led_gpio = <&gpio GPIOY_13 GPIO_ACTIVE_HIGH>;
			led_active = <GPIO_ACTIVE_HIGH>;
			led_type = [42 00];
		};
	};
};
